VERSION ""

NS_ :

BS_:

BU_: ECU Debugger ACU TCM Dash_Panel Steering_Wheel DTI_Inverter GR_Inverter_1 GR_Inverter_2 GR_Inverter_3 GR_Inverter_4 Charging_SDC Fan_Controller_1 Fan_Controller_2 Fan_Controller_3 Fan_Controller_4 Fan_Controller_5 Fan_Controller_6 Fan_Controller_7 Fan_Controller_8 SAM1 SAM2 SAM3 SAM4 SAM5 SAM6 SAM7 SAM8 SAM9 SAM10 SAM11 SAM12 SAM13 SAM14 SAM15 SAM16 SAM17 SAM18 SAM19 SAM20 LV_DC_DC

BO_ 2147483648 Ping: 8 ECU

 SG_ Millis : 7|32@0- (1,0) [-214748.3648|214748.3647] "ms" Vector__XXX

BO_ 1 Ping: 4 ECU

BO_ 2 ECU_status: 44 ECU

 SG_ GR_Inv_4_RPM : 336|16@1+ (1,0) [0.0|65535.0] "RPM" Vector__XXX

 SG_ GR_Inv_4_Temp : 320|16@1+ (1,0) [0.0|65535.0] "Celsius" Vector__XXX

 SG_ GR_Inv_4_AC_current : 304|16@1+ (1,0) [0.0|65535.0] "Amps" Vector__XXX

 SG_ GR_Inv_3_RPM : 288|16@1+ (1,0) [0.0|65535.0] "RPM" Vector__XXX

 SG_ GR_Inv_3_Temp : 272|16@1+ (1,0) [0.0|65535.0] "Celsius" Vector__XXX

 SG_ GR_Inv_3_AC_current : 256|16@1+ (1,0) [0.0|65535.0] "Amps" Vector__XXX

 SG_ GR_Inv_2_RPM : 240|16@1+ (1,0) [0.0|65535.0] "RPM" Vector__XXX

 SG_ GR_Inv_2_Temp : 224|16@1+ (1,0) [0.0|65535.0] "Celsius" Vector__XXX

 SG_ GR_Inv_2_AC_current : 208|16@1+ (1,0) [0.0|65535.0] "Amps" Vector__XXX

 SG_ Inv_1_RPM : 192|16@1+ (1,0) [0.0|65535.0] "RPM" Vector__XXX

 SG_ GR_Inv_1_Temp : 176|16@1+ (1,0) [0.0|65535.0] "Celsius" Vector__XXX

 SG_ GR_Inv_1_AC_current : 160|16@1+ (1,0) [0.0|65535.0] "Amps" Vector__XXX

 SG_ RL_Wheel_RPM : 144|16@1+ (1,0) [0.0|65535.0] "RPM" Vector__XXX

 SG_ RR_Wheel_RPM : 128|16@1+ (1,0) [0.0|65535.0] "RPM" Vector__XXX

 SG_ FL_Wheel_RPM : 112|16@1+ (1,0) [0.0|65535.0] "RPM" Vector__XXX

 SG_ FR_Wheel_RPM : 96|16@1+ (1,0) [0.0|65535.0] "RPM" Vector__XXX

 SG_ Vehicle_Speed : 80|16@1+ (1,0) [0.0|65535.0] "MPH" Vector__XXX

 SG_ Tractive_System_Voltage : 64|16@1+ (1,0) [0.0|65535.0] "Volts" Vector__XXX

 SG_ GLV_State_of_Charge : 56|8@1+ (1,0) [0.0|255.0] "%" Vector__XXX

 SG_ Accumulator_State_of_Charge : 48|8@1+ (1,0) [0.0|255.0] "%" Vector__XXX

 SG_ Max_Cell_Temp : 40|8@1+ (1,0) [0.0|255.0] "Celsius" Vector__XXX

 SG_ Torque_Map : 36|4@1+ (1,0) [0.0|16.0] "~" Vector__XXX

 SG_ Power_Level : 32|4@1+ (1,0) [0.0|15.0] "~" Vector__XXX

 SG_ Reserved_for_future_use : 19|13@1+ (1,0) [0|0] "~" Vector__XXX

 SG_ Steering : 18|1@1+ (1,0) [0.0|1.0] "Bool" Vector__XXX

 SG_ Dash : 17|1@1+ (1,0) [0.0|1.0] "Bool" Vector__XXX

 SG_ Fan_Controller_4 : 16|1@1+ (1,0) [0.0|1.0] "Bool" Vector__XXX

 SG_ Fan_Controller_3 : 15|1@1+ (1,0) [0.0|1.0] "Bool" Vector__XXX

 SG_ Fan_Controller_2 : 14|1@1+ (1,0) [0.0|1.0] "Bool" Vector__XXX

 SG_ Fan_Controller_1 : 13|1@1+ (1,0) [0.0|1.0] "Bool" Vector__XXX

 SG_ GR_Inv_4_Status : 12|1@1+ (1,0) [0.0|1.0] "Bool" Vector__XXX

 SG_ GR_Inv_3_Status : 11|1@1+ (1,0) [0.0|1.0] "Bool" Vector__XXX

 SG_ GR_Inv_2_Status : 10|1@1+ (1,0) [0.0|1.0] "Bool" Vector__XXX

 SG_ GR_Inv_1_Status : 9|1@1+ (1,0) [0.0|1.0] "Bool" Vector__XXX

 SG_ ACU_Node_Status_ : 8|1@1+ (1,0) [0.0|1.0] "Bool" Vector__XXX

 SG_ ECU_State : 0|8@1+ (1,0) [0|0] "Bool" Vector__XXX

BO_ 3 ECU_config: 0 ECU

 SG_ Reserved : 0|1@1+ (1,0) [0|0] "~" Vector__XXX

BO_ 4 ACU_Status: 24 ACU

 SG_ HV_Output_Current : 176|16@1+ (1,0) [0.0|65535.0] "Amps" Vector__XXX

 SG_ HV_Input_Current : 160|16@1+ (1,0) [0.0|65535.0] "Amps" Vector__XXX

 SG_ HV_Output_Voltage : 144|16@1+ (1,0) [0.0|65535.0] "Volts" Vector__XXX

 SG_ HV_Input_Voltage : 128|16@1+ (1,0) [0.0|65535.0] "Volts" Vector__XXX

 SG_ Software_Latch : 122|6@1+ (1,0) [0.0|1.0] "Bool" Vector__XXX

 SG_ IR__State : 121|1@1+ (1,0) [0.0|1.0] "Bool" Vector__XXX

 SG_ IR____Precharge_State : 120|1@1+ (1,0) [0.0|1.0] "Bool" Vector__XXX

 SG_ Precharge_Error : 112|8@1+ (1,0) [0.0|1.0] "Bool" Vector__XXX

 SG_ Under_Voltage_SDC_Warning : 111|1@1+ (1,0) [0.0|1.0] "Bool" Vector__XXX

 SG_ Under_Voltage_12v_Warning : 110|1@1+ (1,0) [0.0|1.0] "Bool" Vector__XXX

 SG_ Under_Voltage_20v_Warning : 109|1@1+ (1,0) [0.0|1.0] "Bool" Vector__XXX

 SG_ Under_Current_Error : 108|1@1+ (1,0) [0.0|1.0] "Bool" Vector__XXX

 SG_ Over_Current_Error : 107|1@1+ (1,0) [0.0|1.0] "Bool" Vector__XXX

 SG_ Under_Voltage_Error : 106|1@1+ (1,0) [0.0|1.0] "Bool" Vector__XXX

 SG_ Over_Voltage_Error : 105|1@1+ (1,0) [0.0|1.0] "Bool" Vector__XXX

 SG_ Over_Temp_Error : 104|1@1+ (1,0) [0.0|1.0] "Bool" Vector__XXX

 SG_ Max_Cell_Temp : 96|8@1+ (1,0) [0.0|255.0] "Celsius" Vector__XXX

 SG_ Min_Cell_Voltage : 88|8@1+ (1,0) [0.0|255.0] "Volts" Vector__XXX

 SG_ SDC_Voltage : 80|8@1+ (1,0) [0.0|255.0] "Volts" Vector__XXX

 SG_ v12v_Voltage : 72|8@1+ (1,0) [0.0|255.0] "Volts" Vector__XXX

 SG_ v20v_Voltage : 64|8@1+ (1,0) [0.0|255.0] "Volts" Vector__XXX

 SG_ GLV_SOC : 56|8@1+ (1,0) [0.0|255.0] "%" Vector__XXX

 SG_ Accumulator_SOC : 48|8@1+ (1,0) [0.0|255.0] "%" Vector__XXX

 SG_ Accumulator_Current : 32|16@1+ (1,0) [0.0|65535.0] "Amps" Vector__XXX

 SG_ TS_Voltage : 16|16@1+ (1,0) [0.0|65535.0] "Volts" Vector__XXX

 SG_ Accumulator_Voltage : 0|16@1+ (1,0) [0.0|65535.0] "Volts" Vector__XXX

BO_ 5 ACU_Precharge: 1 ACU

 SG_ Set_TS_Active : 0|8@1+ (1,0) [0.0|1.0] "Bool" Vector__XXX

BO_ 6 ACU_Config_Charge_Parameters: 4 ACU

 SG_ Charge_Current : 16|16@1+ (1,0) [0.0|65535.0] "Amps" Vector__XXX

 SG_ Charge_Voltage : 0|16@1+ (1,0) [0.0|65535.0] "Volts" Vector__XXX

BO_ 7 ACU_Config_Operational_Parameter: 2 ACU

 SG_ Max_Cell_Temperature : 8|8@1+ (1,0) [0.0|255.0] "Celsius" Vector__XXX

 SG_ Minimium_Cell_Voltage : 0|8@1+ (1,0) [0.0|255.0] "Volts" Vector__XXX

BO_ 8 ACU_Cell_Data_1: 64 ACU

 SG_ Cell_31_Temp : 504|8@1+ (1,0) [0.0|255.0] "Celsius" Vector__XXX

 SG_ Cell_31_Voltage : 496|8@1+ (1,0) [0.0|255.0] "Volts" Vector__XXX

 SG_ Cell_30_Temp : 488|8@1+ (1,0) [0.0|255.0] "Celsius" Vector__XXX

 SG_ Cell_30_Voltage : 480|8@1+ (1,0) [0.0|255.0] "Volts" Vector__XXX

 SG_ Cell_29_Temp : 472|8@1+ (1,0) [0.0|255.0] "Celsius" Vector__XXX

 SG_ Cell_29_Voltage : 464|8@1+ (1,0) [0.0|255.0] "Volts" Vector__XXX

 SG_ Cell_28_Temp : 456|8@1+ (1,0) [0.0|255.0] "Celsius" Vector__XXX

 SG_ Cell_28_Voltage : 448|8@1+ (1,0) [0.0|255.0] "Volts" Vector__XXX

 SG_ Cell_27_Temp : 440|8@1+ (1,0) [0.0|255.0] "Celsius" Vector__XXX

 SG_ Cell_27_Voltage : 432|8@1+ (1,0) [0.0|255.0] "Volts" Vector__XXX

 SG_ Cell_26_Temp : 424|8@1+ (1,0) [0.0|255.0] "Celsius" Vector__XXX

 SG_ Cell_26_Voltage : 416|8@1+ (1,0) [0.0|255.0] "Volts" Vector__XXX

 SG_ Cell_25_Temp : 408|8@1+ (1,0) [0.0|255.0] "Celsius" Vector__XXX

 SG_ Cell_25_Voltage : 400|8@1+ (1,0) [0.0|255.0] "Volts" Vector__XXX

 SG_ Cell_24_Temp : 392|8@1+ (1,0) [0.0|255.0] "Celsius" Vector__XXX

 SG_ Cell_24_Voltage : 384|8@1+ (1,0) [0.0|255.0] "Volts" Vector__XXX

 SG_ Cell_23_Temp : 376|8@1+ (1,0) [0.0|255.0] "Celsius" Vector__XXX

 SG_ Cell_23_Voltage : 368|8@1+ (1,0) [0.0|255.0] "Volts" Vector__XXX

 SG_ Cell_22_Temp : 360|8@1+ (1,0) [0.0|255.0] "Celsius" Vector__XXX

 SG_ Cell_22_Voltage : 352|8@1+ (1,0) [0.0|255.0] "Volts" Vector__XXX

 SG_ Cell_21_Temp : 344|8@1+ (1,0) [0.0|255.0] "Celsius" Vector__XXX

 SG_ Cell_21_Voltage : 336|8@1+ (1,0) [0.0|255.0] "Volts" Vector__XXX

 SG_ Cell_20_Temp : 328|8@1+ (1,0) [0.0|255.0] "Celsius" Vector__XXX

 SG_ Cell_20_Voltage : 320|8@1+ (1,0) [0.0|255.0] "Volts" Vector__XXX

 SG_ Cell_19_Temp : 312|8@1+ (1,0) [0.0|255.0] "Celsius" Vector__XXX

 SG_ Cell_19_Voltage : 304|8@1+ (1,0) [0.0|255.0] "Volts" Vector__XXX

 SG_ Cell_18_Temp : 296|8@1+ (1,0) [0.0|255.0] "Celsius" Vector__XXX

 SG_ Cell_18_Voltage : 288|8@1+ (1,0) [0.0|255.0] "Volts" Vector__XXX

 SG_ Cell_17_Temp : 280|8@1+ (1,0) [0.0|255.0] "Celsius" Vector__XXX

 SG_ Cell_17_Voltage : 272|8@1+ (1,0) [0.0|255.0] "Volts" Vector__XXX

 SG_ Cell_16_Temp : 264|8@1+ (1,0) [0.0|255.0] "Celsius" Vector__XXX

 SG_ Cell_16_Voltage : 256|8@1+ (1,0) [0.0|255.0] "Volts" Vector__XXX

 SG_ Cell_15_Temp : 248|8@1+ (1,0) [0.0|255.0] "Celsius" Vector__XXX

 SG_ Cell_15_Voltage : 240|8@1+ (1,0) [0.0|255.0] "Volts" Vector__XXX

 SG_ Cell_14_Temp : 232|8@1+ (1,0) [0.0|255.0] "Celsius" Vector__XXX

 SG_ Cell_14_Voltage : 224|8@1+ (1,0) [0.0|255.0] "Volts" Vector__XXX

 SG_ Cell_13_Temp : 216|8@1+ (1,0) [0.0|255.0] "Celsius" Vector__XXX

 SG_ Cell_13_Voltage : 208|8@1+ (1,0) [0.0|255.0] "Volts" Vector__XXX

 SG_ Cell_12_Temp : 200|8@1+ (1,0) [0.0|255.0] "Celsius" Vector__XXX

 SG_ Cell_12_Voltage : 192|8@1+ (1,0) [0.0|255.0] "Volts" Vector__XXX

 SG_ Cell_11_Temp : 184|8@1+ (1,0) [0.0|255.0] "Celsius" Vector__XXX

 SG_ Cell_11_Voltage : 176|8@1+ (1,0) [0.0|255.0] "Volts" Vector__XXX

 SG_ Cell_10_Temp : 168|8@1+ (1,0) [0.0|255.0] "Celsius" Vector__XXX

 SG_ Cell_10_Voltage : 160|8@1+ (1,0) [0.0|255.0] "Volts" Vector__XXX

 SG_ Cell_9_Temp : 152|8@1+ (1,0) [0.0|255.0] "Celsius" Vector__XXX

 SG_ Cell_9_Voltage : 144|8@1+ (1,0) [0.0|255.0] "Volts" Vector__XXX

 SG_ Cell_8_Temp : 136|8@1+ (1,0) [0.0|255.0] "Celsius" Vector__XXX

 SG_ Cell_8_Voltage : 128|8@1+ (1,0) [0.0|255.0] "Volts" Vector__XXX

 SG_ Cell_7_Temp : 120|8@1+ (1,0) [0.0|255.0] "Celsius" Vector__XXX

 SG_ Cell_7_Voltage : 112|8@1+ (1,0) [0.0|255.0] "Volts" Vector__XXX

 SG_ Cell_6_Temp : 104|8@1+ (1,0) [0.0|255.0] "Celsius" Vector__XXX

 SG_ Cell_6_Voltage : 96|8@1+ (1,0) [0.0|255.0] "Volts" Vector__XXX

 SG_ Cell_5_Temp : 88|8@1+ (1,0) [0.0|255.0] "Celsius" Vector__XXX

 SG_ Cell_5_Voltage : 80|8@1+ (1,0) [0.0|255.0] "Volts" Vector__XXX

 SG_ Cell_4_Temp : 72|8@1+ (1,0) [0.0|255.0] "Celsius" Vector__XXX

 SG_ Cell_4_Voltage : 64|8@1+ (1,0) [0.0|255.0] "Volts" Vector__XXX

 SG_ Cell_3_Temp : 56|8@1+ (1,0) [0.0|255.0] "Celsius" Vector__XXX

 SG_ Cell_3_Voltage : 48|8@1+ (1,0) [0.0|255.0] "Volts" Vector__XXX

 SG_ Cell_2_Temp : 40|8@1+ (1,0) [0.0|255.0] "Celsius" Vector__XXX

 SG_ Cell_2_Voltage : 32|8@1+ (1,0) [0.0|255.0] "Volts" Vector__XXX

 SG_ Cell_1_Temp : 24|8@1+ (1,0) [0.0|255.0] "Celsius" Vector__XXX

 SG_ Cell_1_Voltage : 16|8@1+ (1,0) [0.0|255.0] "Volts" Vector__XXX

 SG_ Cell_0_Temp : 8|8@1+ (1,0) [0.0|255.0] "Celsius" Vector__XXX

 SG_ Cell_0_Voltage : 0|8@1+ (1,0) [0.0|255.0] "Volts" Vector__XXX

BO_ 9 ACU_Cell_Data_2: 64 ACU

 SG_ Cell_63_Temp : 504|8@1+ (1,0) [0.0|255.0] "Celsius" Vector__XXX

 SG_ Cell_63_Voltage : 496|8@1+ (1,0) [0.0|255.0] "Volts" Vector__XXX

 SG_ Cell_62_Temp : 488|8@1+ (1,0) [0.0|255.0] "Celsius" Vector__XXX

 SG_ Cell_62_Voltage : 480|8@1+ (1,0) [0.0|255.0] "Volts" Vector__XXX

 SG_ Cell_61_Temp : 472|8@1+ (1,0) [0.0|255.0] "Celsius" Vector__XXX

 SG_ Cell_61_Voltage : 464|8@1+ (1,0) [0.0|255.0] "Volts" Vector__XXX

 SG_ Cell_60_Temp : 456|8@1+ (1,0) [0.0|255.0] "Celsius" Vector__XXX

 SG_ Cell_60_Voltage : 448|8@1+ (1,0) [0.0|255.0] "Volts" Vector__XXX

 SG_ Cell_59_Temp : 440|8@1+ (1,0) [0.0|255.0] "Celsius" Vector__XXX

 SG_ Cell_59_Voltage : 432|8@1+ (1,0) [0.0|255.0] "Volts" Vector__XXX

 SG_ Cell_58_Temp : 424|8@1+ (1,0) [0.0|255.0] "Celsius" Vector__XXX

 SG_ Cell_58_Voltage : 416|8@1+ (1,0) [0.0|255.0] "Volts" Vector__XXX

 SG_ Cell_57_Temp : 408|8@1+ (1,0) [0.0|255.0] "Celsius" Vector__XXX

 SG_ Cell_57_Voltage : 400|8@1+ (1,0) [0.0|255.0] "Volts" Vector__XXX

 SG_ Cell_56_Temp : 392|8@1+ (1,0) [0.0|255.0] "Celsius" Vector__XXX

 SG_ Cell_56_Voltage : 384|8@1+ (1,0) [0.0|255.0] "Volts" Vector__XXX

 SG_ Cell_55_Temp : 376|8@1+ (1,0) [0.0|255.0] "Celsius" Vector__XXX

 SG_ Cell_55_Voltage : 368|8@1+ (1,0) [0.0|255.0] "Volts" Vector__XXX

 SG_ Cell_54_Temp : 360|8@1+ (1,0) [0.0|255.0] "Celsius" Vector__XXX

 SG_ Cell_54_Voltage : 352|8@1+ (1,0) [0.0|255.0] "Volts" Vector__XXX

 SG_ Cell_53_Temp : 344|8@1+ (1,0) [0.0|255.0] "Celsius" Vector__XXX

 SG_ Cell_53_Voltage : 336|8@1+ (1,0) [0.0|255.0] "Volts" Vector__XXX

 SG_ Cell_52_Temp : 328|8@1+ (1,0) [0.0|255.0] "Celsius" Vector__XXX

 SG_ Cell_52_Voltage : 320|8@1+ (1,0) [0.0|255.0] "Volts" Vector__XXX

 SG_ Cell_51_Temp : 312|8@1+ (1,0) [0.0|255.0] "Celsius" Vector__XXX

 SG_ Cell_51_Voltage : 304|8@1+ (1,0) [0.0|255.0] "Volts" Vector__XXX

 SG_ Cell_50_Temp : 296|8@1+ (1,0) [0.0|255.0] "Celsius" Vector__XXX

 SG_ Cell_50_Voltage : 288|8@1+ (1,0) [0.0|255.0] "Volts" Vector__XXX

 SG_ Cell_49_Temp : 280|8@1+ (1,0) [0.0|255.0] "Celsius" Vector__XXX

 SG_ Cell_49_Voltage : 272|8@1+ (1,0) [0.0|255.0] "Volts" Vector__XXX

 SG_ Cell_48_Temp : 264|8@1+ (1,0) [0.0|255.0] "Celsius" Vector__XXX

 SG_ Cell_48_Voltage : 256|8@1+ (1,0) [0.0|255.0] "Volts" Vector__XXX

 SG_ Cell_47_Temp : 248|8@1+ (1,0) [0.0|255.0] "Celsius" Vector__XXX

 SG_ Cell_47_Voltage : 240|8@1+ (1,0) [0.0|255.0] "Volts" Vector__XXX

 SG_ Cell_46_Temp : 232|8@1+ (1,0) [0.0|255.0] "Celsius" Vector__XXX

 SG_ Cell_46_Voltage : 224|8@1+ (1,0) [0.0|255.0] "Volts" Vector__XXX

 SG_ Cell_45_Temp : 216|8@1+ (1,0) [0.0|255.0] "Celsius" Vector__XXX

 SG_ Cell_45_Voltage : 208|8@1+ (1,0) [0.0|255.0] "Volts" Vector__XXX

 SG_ Cell_44_Temp : 200|8@1+ (1,0) [0.0|255.0] "Celsius" Vector__XXX

 SG_ Cell_44_Voltage : 192|8@1+ (1,0) [0.0|255.0] "Volts" Vector__XXX

 SG_ Cell_43_Temp : 184|8@1+ (1,0) [0.0|255.0] "Celsius" Vector__XXX

 SG_ Cell_43_Voltage : 176|8@1+ (1,0) [0.0|255.0] "Volts" Vector__XXX

 SG_ Cell_42_Temp : 168|8@1+ (1,0) [0.0|255.0] "Celsius" Vector__XXX

 SG_ Cell_42_Voltage : 160|8@1+ (1,0) [0.0|255.0] "Volts" Vector__XXX

 SG_ Cell_41_Temp : 152|8@1+ (1,0) [0.0|255.0] "Celsius" Vector__XXX

 SG_ Cell_41_Voltage : 144|8@1+ (1,0) [0.0|255.0] "Volts" Vector__XXX

 SG_ Cell_40_Temp : 136|8@1+ (1,0) [0.0|255.0] "Celsius" Vector__XXX

 SG_ Cell_40_Voltage : 128|8@1+ (1,0) [0.0|255.0] "Volts" Vector__XXX

 SG_ Cell_39_Temp : 120|8@1+ (1,0) [0.0|255.0] "Celsius" Vector__XXX

 SG_ Cell_39_Voltage : 112|8@1+ (1,0) [0.0|255.0] "Volts" Vector__XXX

 SG_ Cell_38_Temp : 104|8@1+ (1,0) [0.0|255.0] "Celsius" Vector__XXX

 SG_ Cell_38_Voltage : 96|8@1+ (1,0) [0.0|255.0] "Volts" Vector__XXX

 SG_ Cell_37_Temp : 88|8@1+ (1,0) [0.0|255.0] "Celsius" Vector__XXX

 SG_ Cell_37_Voltage : 80|8@1+ (1,0) [0.0|255.0] "Volts" Vector__XXX

 SG_ Cell_36_Temp : 72|8@1+ (1,0) [0.0|255.0] "Celsius" Vector__XXX

 SG_ Cell_36_Voltage : 64|8@1+ (1,0) [0.0|255.0] "Volts" Vector__XXX

 SG_ Cell_35_Temp : 56|8@1+ (1,0) [0.0|255.0] "Celsius" Vector__XXX

 SG_ Cell_35_Voltage : 48|8@1+ (1,0) [0.0|255.0] "Volts" Vector__XXX

 SG_ Cell_34_Temp : 40|8@1+ (1,0) [0.0|255.0] "Celsius" Vector__XXX

 SG_ Cell_34_Voltage : 32|8@1+ (1,0) [0.0|255.0] "Volts" Vector__XXX

 SG_ Cell_33_Temp : 24|8@1+ (1,0) [0.0|255.0] "Celsius" Vector__XXX

 SG_ Cell_33_Voltage : 16|8@1+ (1,0) [0.0|255.0] "Volts" Vector__XXX

 SG_ Cell_32_Temp : 8|8@1+ (1,0) [0.0|255.0] "Celsius" Vector__XXX

 SG_ Cell_32_Voltage : 0|8@1+ (1,0) [0.0|255.0] "Volts" Vector__XXX

BO_ 10 ACU_Cell_Data_3: 64 ACU

 SG_ Cell_95_Temp : 504|8@1+ (1,0) [0.0|255.0] "Celsius" Vector__XXX

 SG_ Cell_95_Voltage : 496|8@1+ (1,0) [0.0|255.0] "Volts" Vector__XXX

 SG_ Cell_94_Temp : 488|8@1+ (1,0) [0.0|255.0] "Celsius" Vector__XXX

 SG_ Cell_94_Voltage : 480|8@1+ (1,0) [0.0|255.0] "Volts" Vector__XXX

 SG_ Cell_93_Temp : 472|8@1+ (1,0) [0.0|255.0] "Celsius" Vector__XXX

 SG_ Cell_93_Voltage : 464|8@1+ (1,0) [0.0|255.0] "Volts" Vector__XXX

 SG_ Cell_92_Temp : 456|8@1+ (1,0) [0.0|255.0] "Celsius" Vector__XXX

 SG_ Cell_92_Voltage : 448|8@1+ (1,0) [0.0|255.0] "Volts" Vector__XXX

 SG_ Cell_91_Temp : 440|8@1+ (1,0) [0.0|255.0] "Celsius" Vector__XXX

 SG_ Cell_91_Voltage : 432|8@1+ (1,0) [0.0|255.0] "Volts" Vector__XXX

 SG_ Cell_90_Temp : 424|8@1+ (1,0) [0.0|255.0] "Celsius" Vector__XXX

 SG_ Cell_90_Voltage : 416|8@1+ (1,0) [0.0|255.0] "Volts" Vector__XXX

 SG_ Cell_89_Temp : 408|8@1+ (1,0) [0.0|255.0] "Celsius" Vector__XXX

 SG_ Cell_89_Voltage : 400|8@1+ (1,0) [0.0|255.0] "Volts" Vector__XXX

 SG_ Cell_88_Temp : 392|8@1+ (1,0) [0.0|255.0] "Celsius" Vector__XXX

 SG_ Cell_88_Voltage : 384|8@1+ (1,0) [0.0|255.0] "Volts" Vector__XXX

 SG_ Cell_87_Temp : 376|8@1+ (1,0) [0.0|255.0] "Celsius" Vector__XXX

 SG_ Cell_87_Voltage : 368|8@1+ (1,0) [0.0|255.0] "Volts" Vector__XXX

 SG_ Cell_86_Temp : 360|8@1+ (1,0) [0.0|255.0] "Celsius" Vector__XXX

 SG_ Cell_86_Voltage : 352|8@1+ (1,0) [0.0|255.0] "Volts" Vector__XXX

 SG_ Cell_85_Temp : 344|8@1+ (1,0) [0.0|255.0] "Celsius" Vector__XXX

 SG_ Cell_85_Voltage : 336|8@1+ (1,0) [0.0|255.0] "Volts" Vector__XXX

 SG_ Cell_84_Temp : 328|8@1+ (1,0) [0.0|255.0] "Celsius" Vector__XXX

 SG_ Cell_84_Voltage : 320|8@1+ (1,0) [0.0|255.0] "Volts" Vector__XXX

 SG_ Cell_83_Temp : 312|8@1+ (1,0) [0.0|255.0] "Celsius" Vector__XXX

 SG_ Cell_83_Voltage : 304|8@1+ (1,0) [0.0|255.0] "Volts" Vector__XXX

 SG_ Cell_82_Temp : 296|8@1+ (1,0) [0.0|255.0] "Celsius" Vector__XXX

 SG_ Cell_82_Voltage : 288|8@1+ (1,0) [0.0|255.0] "Volts" Vector__XXX

 SG_ Cell_81_Temp : 280|8@1+ (1,0) [0.0|255.0] "Celsius" Vector__XXX

 SG_ Cell_81_Voltage : 272|8@1+ (1,0) [0.0|255.0] "Volts" Vector__XXX

 SG_ Cell_80_Temp : 264|8@1+ (1,0) [0.0|255.0] "Celsius" Vector__XXX

 SG_ Cell_80_Voltage : 256|8@1+ (1,0) [0.0|255.0] "Volts" Vector__XXX

 SG_ Cell_79_Temp : 248|8@1+ (1,0) [0.0|255.0] "Celsius" Vector__XXX

 SG_ Cell_79_Voltage : 240|8@1+ (1,0) [0.0|255.0] "Volts" Vector__XXX

 SG_ Cell_78_Temp : 232|8@1+ (1,0) [0.0|255.0] "Celsius" Vector__XXX

 SG_ Cell_78_Voltage : 224|8@1+ (1,0) [0.0|255.0] "Volts" Vector__XXX

 SG_ Cell_77_Temp : 216|8@1+ (1,0) [0.0|255.0] "Celsius" Vector__XXX

 SG_ Cell_77_Voltage : 208|8@1+ (1,0) [0.0|255.0] "Volts" Vector__XXX

 SG_ Cell_76_Temp : 200|8@1+ (1,0) [0.0|255.0] "Celsius" Vector__XXX

 SG_ Cell_76_Voltage : 192|8@1+ (1,0) [0.0|255.0] "Volts" Vector__XXX

 SG_ Cell_75_Temp : 184|8@1+ (1,0) [0.0|255.0] "Celsius" Vector__XXX

 SG_ Cell_75_Voltage : 176|8@1+ (1,0) [0.0|255.0] "Volts" Vector__XXX

 SG_ Cell_74_Temp : 168|8@1+ (1,0) [0.0|255.0] "Celsius" Vector__XXX

 SG_ Cell_74_Voltage : 160|8@1+ (1,0) [0.0|255.0] "Volts" Vector__XXX

 SG_ Cell_73_Temp : 152|8@1+ (1,0) [0.0|255.0] "Celsius" Vector__XXX

 SG_ Cell_73_Voltage : 144|8@1+ (1,0) [0.0|255.0] "Volts" Vector__XXX

 SG_ Cell_72_Temp : 136|8@1+ (1,0) [0.0|255.0] "Celsius" Vector__XXX

 SG_ Cell_72_Voltage : 128|8@1+ (1,0) [0.0|255.0] "Volts" Vector__XXX

 SG_ Cell_71_Temp : 120|8@1+ (1,0) [0.0|255.0] "Celsius" Vector__XXX

 SG_ Cell_71_Voltage : 112|8@1+ (1,0) [0.0|255.0] "Volts" Vector__XXX

 SG_ Cell_70_Temp : 104|8@1+ (1,0) [0.0|255.0] "Celsius" Vector__XXX

 SG_ Cell_70_Voltage : 96|8@1+ (1,0) [0.0|255.0] "Volts" Vector__XXX

 SG_ Cell_69_Temp : 88|8@1+ (1,0) [0.0|255.0] "Celsius" Vector__XXX

 SG_ Cell_69_Voltage : 80|8@1+ (1,0) [0.0|255.0] "Volts" Vector__XXX

 SG_ Cell_68_Temp : 72|8@1+ (1,0) [0.0|255.0] "Celsius" Vector__XXX

 SG_ Cell_68_Voltage : 64|8@1+ (1,0) [0.0|255.0] "Volts" Vector__XXX

 SG_ Cell_67_Temp : 56|8@1+ (1,0) [0.0|255.0] "Celsius" Vector__XXX

 SG_ Cell_67_Voltage : 48|8@1+ (1,0) [0.0|255.0] "Volts" Vector__XXX

 SG_ Cell_66_Temp : 40|8@1+ (1,0) [0.0|255.0] "Celsius" Vector__XXX

 SG_ Cell_66_Voltage : 32|8@1+ (1,0) [0.0|255.0] "Volts" Vector__XXX

 SG_ Cell_65_Temp : 24|8@1+ (1,0) [0.0|255.0] "Celsius" Vector__XXX

 SG_ Cell_65_Voltage : 16|8@1+ (1,0) [0.0|255.0] "Volts" Vector__XXX

 SG_ Cell_64_Temp : 8|8@1+ (1,0) [0.0|255.0] "Celsius" Vector__XXX

 SG_ Cell_64_Voltage : 0|8@1+ (1,0) [0.0|255.0] "Volts" Vector__XXX

BO_ 11 ACU_Cell_Data_4: 64 ACU

 SG_ Cell_127_Temp : 504|8@1+ (1,0) [0.0|255.0] "Celsius" Vector__XXX

 SG_ Cell_127_Voltage : 496|8@1+ (1,0) [0.0|255.0] "Volts" Vector__XXX

 SG_ Cell_126_Temp : 488|8@1+ (1,0) [0.0|255.0] "Celsius" Vector__XXX

 SG_ Cell_126_Voltage : 480|8@1+ (1,0) [0.0|255.0] "Volts" Vector__XXX

 SG_ Cell_125_Temp : 472|8@1+ (1,0) [0.0|255.0] "Celsius" Vector__XXX

 SG_ Cell_125_Voltage : 464|8@1+ (1,0) [0.0|255.0] "Volts" Vector__XXX

 SG_ Cell_124_Temp : 456|8@1+ (1,0) [0.0|255.0] "Celsius" Vector__XXX

 SG_ Cell_124_Voltage : 448|8@1+ (1,0) [0.0|255.0] "Volts" Vector__XXX

 SG_ Cell_123_Temp : 440|8@1+ (1,0) [0.0|255.0] "Celsius" Vector__XXX

 SG_ Cell_123_Voltage : 432|8@1+ (1,0) [0.0|255.0] "Volts" Vector__XXX

 SG_ Cell_122_Temp : 424|8@1+ (1,0) [0.0|255.0] "Celsius" Vector__XXX

 SG_ Cell_122_Voltage : 416|8@1+ (1,0) [0.0|255.0] "Volts" Vector__XXX

 SG_ Cell_121_Temp : 408|8@1+ (1,0) [0.0|255.0] "Celsius" Vector__XXX

 SG_ Cell_121_Voltage : 400|8@1+ (1,0) [0.0|255.0] "Volts" Vector__XXX

 SG_ Cell_120_Temp : 392|8@1+ (1,0) [0.0|255.0] "Celsius" Vector__XXX

 SG_ Cell_120_Voltage : 384|8@1+ (1,0) [0.0|255.0] "Volts" Vector__XXX

 SG_ Cell_119_Temp : 376|8@1+ (1,0) [0.0|255.0] "Celsius" Vector__XXX

 SG_ Cell_119_Voltage : 368|8@1+ (1,0) [0.0|255.0] "Volts" Vector__XXX

 SG_ Cell_118_Temp : 360|8@1+ (1,0) [0.0|255.0] "Celsius" Vector__XXX

 SG_ Cell_118_Voltage : 352|8@1+ (1,0) [0.0|255.0] "Volts" Vector__XXX

 SG_ Cell_117_Temp : 344|8@1+ (1,0) [0.0|255.0] "Celsius" Vector__XXX

 SG_ Cell_117_Voltage : 336|8@1+ (1,0) [0.0|255.0] "Volts" Vector__XXX

 SG_ Cell_116_Temp : 328|8@1+ (1,0) [0.0|255.0] "Celsius" Vector__XXX

 SG_ Cell_116_Voltage : 320|8@1+ (1,0) [0.0|255.0] "Volts" Vector__XXX

 SG_ Cell_115_Temp : 312|8@1+ (1,0) [0.0|255.0] "Celsius" Vector__XXX

 SG_ Cell_115_Voltage : 304|8@1+ (1,0) [0.0|255.0] "Volts" Vector__XXX

 SG_ Cell_114_Temp : 296|8@1+ (1,0) [0.0|255.0] "Celsius" Vector__XXX

 SG_ Cell_114_Voltage : 288|8@1+ (1,0) [0.0|255.0] "Volts" Vector__XXX

 SG_ Cell_113_Temp : 280|8@1+ (1,0) [0.0|255.0] "Celsius" Vector__XXX

 SG_ Cell_113_Voltage : 272|8@1+ (1,0) [0.0|255.0] "Volts" Vector__XXX

 SG_ Cell_112_Temp : 264|8@1+ (1,0) [0.0|255.0] "Celsius" Vector__XXX

 SG_ Cell_112_Voltage : 256|8@1+ (1,0) [0.0|255.0] "Volts" Vector__XXX

 SG_ Cell_111_Temp : 248|8@1+ (1,0) [0.0|255.0] "Celsius" Vector__XXX

 SG_ Cell_111_Voltage : 240|8@1+ (1,0) [0.0|255.0] "Volts" Vector__XXX

 SG_ Cell_110_Temp : 232|8@1+ (1,0) [0.0|255.0] "Celsius" Vector__XXX

 SG_ Cell_110_Voltage : 224|8@1+ (1,0) [0.0|255.0] "Volts" Vector__XXX

 SG_ Cell_109_Temp : 216|8@1+ (1,0) [0.0|255.0] "Celsius" Vector__XXX

 SG_ Cell_109_Voltage : 208|8@1+ (1,0) [0.0|255.0] "Volts" Vector__XXX

 SG_ Cell_108_Temp : 200|8@1+ (1,0) [0.0|255.0] "Celsius" Vector__XXX

 SG_ Cell_108_Voltage : 192|8@1+ (1,0) [0.0|255.0] "Volts" Vector__XXX

 SG_ Cell_107_Temp : 184|8@1+ (1,0) [0.0|255.0] "Celsius" Vector__XXX

 SG_ Cell_107_Voltage : 176|8@1+ (1,0) [0.0|255.0] "Volts" Vector__XXX

 SG_ Cell_106_Temp : 168|8@1+ (1,0) [0.0|255.0] "Celsius" Vector__XXX

 SG_ Cell_106_Voltage : 160|8@1+ (1,0) [0.0|255.0] "Volts" Vector__XXX

 SG_ Cell_105_Temp : 152|8@1+ (1,0) [0.0|255.0] "Celsius" Vector__XXX

 SG_ Cell_105_Voltage : 144|8@1+ (1,0) [0.0|255.0] "Volts" Vector__XXX

 SG_ Cell_104_Temp : 136|8@1+ (1,0) [0.0|255.0] "Celsius" Vector__XXX

 SG_ Cell_104_Voltage : 128|8@1+ (1,0) [0.0|255.0] "Volts" Vector__XXX

 SG_ Cell_103_Temp : 120|8@1+ (1,0) [0.0|255.0] "Celsius" Vector__XXX

 SG_ Cell_103_Voltage : 112|8@1+ (1,0) [0.0|255.0] "Volts" Vector__XXX

 SG_ Cell_102_Temp : 104|8@1+ (1,0) [0.0|255.0] "Celsius" Vector__XXX

 SG_ Cell_102_Voltage : 96|8@1+ (1,0) [0.0|255.0] "Volts" Vector__XXX

 SG_ Cell_101_Temp : 88|8@1+ (1,0) [0.0|255.0] "Celsius" Vector__XXX

 SG_ Cell_101_Voltage : 80|8@1+ (1,0) [0.0|255.0] "Volts" Vector__XXX

 SG_ Cell_100_Temp : 72|8@1+ (1,0) [0.0|255.0] "Celsius" Vector__XXX

 SG_ Cell_100_Voltage : 64|8@1+ (1,0) [0.0|255.0] "Volts" Vector__XXX

 SG_ Cell_99_Temp : 56|8@1+ (1,0) [0.0|255.0] "Celsius" Vector__XXX

 SG_ Cell_99_Voltage : 48|8@1+ (1,0) [0.0|255.0] "Volts" Vector__XXX

 SG_ Cell_98_Temp : 40|8@1+ (1,0) [0.0|255.0] "Celsius" Vector__XXX

 SG_ Cell_98_Voltage : 32|8@1+ (1,0) [0.0|255.0] "Volts" Vector__XXX

 SG_ Cell_97_Temp : 24|8@1+ (1,0) [0.0|255.0] "Celsius" Vector__XXX

 SG_ Cell_97_Voltage : 16|8@1+ (1,0) [0.0|255.0] "Volts" Vector__XXX

 SG_ Cell_96_Temp : 8|8@1+ (1,0) [0.0|255.0] "Celsius" Vector__XXX

 SG_ Cell_96_Voltage : 0|8@1+ (1,0) [0.0|255.0] "Volts" Vector__XXX

BO_ 12 ACU_Cell_Data_5: 64 ACU

 SG_ Cell_159_Temp : 504|8@1+ (1,0) [0.0|255.0] "Celsius" Vector__XXX

 SG_ Cell_159_Voltage : 496|8@1+ (1,0) [0.0|255.0] "Volts" Vector__XXX

 SG_ Cell_158_Temp : 488|8@1+ (1,0) [0.0|255.0] "Celsius" Vector__XXX

 SG_ Cell_158_Voltage : 480|8@1+ (1,0) [0.0|255.0] "Volts" Vector__XXX

 SG_ Cell_157_Temp : 472|8@1+ (1,0) [0.0|255.0] "Celsius" Vector__XXX

 SG_ Cell_157_Voltage : 464|8@1+ (1,0) [0.0|255.0] "Volts" Vector__XXX

 SG_ Cell_156_Temp : 456|8@1+ (1,0) [0.0|255.0] "Celsius" Vector__XXX

 SG_ Cell_156_Voltage : 448|8@1+ (1,0) [0.0|255.0] "Volts" Vector__XXX

 SG_ Cell_155_Temp : 440|8@1+ (1,0) [0.0|255.0] "Celsius" Vector__XXX

 SG_ Cell_155_Voltage : 432|8@1+ (1,0) [0.0|255.0] "Volts" Vector__XXX

 SG_ Cell_154_Temp : 424|8@1+ (1,0) [0.0|255.0] "Celsius" Vector__XXX

 SG_ Cell_154_Voltage : 416|8@1+ (1,0) [0.0|255.0] "Volts" Vector__XXX

 SG_ Cell_153_Temp : 408|8@1+ (1,0) [0.0|255.0] "Celsius" Vector__XXX

 SG_ Cell_153_Voltage : 400|8@1+ (1,0) [0.0|255.0] "Volts" Vector__XXX

 SG_ Cell_152_Temp : 392|8@1+ (1,0) [0.0|255.0] "Celsius" Vector__XXX

 SG_ Cell_152_Voltage : 384|8@1+ (1,0) [0.0|255.0] "Volts" Vector__XXX

 SG_ Cell_151_Temp : 376|8@1+ (1,0) [0.0|255.0] "Celsius" Vector__XXX

 SG_ Cell_151_Voltage : 368|8@1+ (1,0) [0.0|255.0] "Volts" Vector__XXX

 SG_ Cell_150_Temp : 360|8@1+ (1,0) [0.0|255.0] "Celsius" Vector__XXX

 SG_ Cell_150_Voltage : 352|8@1+ (1,0) [0.0|255.0] "Volts" Vector__XXX

 SG_ Cell_149_Temp : 344|8@1+ (1,0) [0.0|255.0] "Celsius" Vector__XXX

 SG_ Cell_149_Voltage : 336|8@1+ (1,0) [0.0|255.0] "Volts" Vector__XXX

 SG_ Cell_148_Temp : 328|8@1+ (1,0) [0.0|255.0] "Celsius" Vector__XXX

 SG_ Cell_148_Voltage : 320|8@1+ (1,0) [0.0|255.0] "Volts" Vector__XXX

 SG_ Cell_147_Temp : 312|8@1+ (1,0) [0.0|255.0] "Celsius" Vector__XXX

 SG_ Cell_147_Voltage : 304|8@1+ (1,0) [0.0|255.0] "Volts" Vector__XXX

 SG_ Cell_146_Temp : 296|8@1+ (1,0) [0.0|255.0] "Celsius" Vector__XXX

 SG_ Cell_146_Voltage : 288|8@1+ (1,0) [0.0|255.0] "Volts" Vector__XXX

 SG_ Cell_145_Temp : 280|8@1+ (1,0) [0.0|255.0] "Celsius" Vector__XXX

 SG_ Cell_145_Voltage : 272|8@1+ (1,0) [0.0|255.0] "Volts" Vector__XXX

 SG_ Cell_144_Temp : 264|8@1+ (1,0) [0.0|255.0] "Celsius" Vector__XXX

 SG_ Cell_144_Voltage : 256|8@1+ (1,0) [0.0|255.0] "Volts" Vector__XXX

 SG_ Cell_143_Temp : 248|8@1+ (1,0) [0.0|255.0] "Celsius" Vector__XXX

 SG_ Cell_143_Voltage : 240|8@1+ (1,0) [0.0|255.0] "Volts" Vector__XXX

 SG_ Cell_142_Temp : 232|8@1+ (1,0) [0.0|255.0] "Celsius" Vector__XXX

 SG_ Cell_142_Voltage : 224|8@1+ (1,0) [0.0|255.0] "Volts" Vector__XXX

 SG_ Cell_141_Temp : 216|8@1+ (1,0) [0.0|255.0] "Celsius" Vector__XXX

 SG_ Cell_141_Voltage : 208|8@1+ (1,0) [0.0|255.0] "Volts" Vector__XXX

 SG_ Cell_140_Temp : 200|8@1+ (1,0) [0.0|255.0] "Celsius" Vector__XXX

 SG_ Cell_140_Voltage : 192|8@1+ (1,0) [0.0|255.0] "Volts" Vector__XXX

 SG_ Cell_139_Temp : 184|8@1+ (1,0) [0.0|255.0] "Celsius" Vector__XXX

 SG_ Cell_139_Voltage : 176|8@1+ (1,0) [0.0|255.0] "Volts" Vector__XXX

 SG_ Cell_138_Temp : 168|8@1+ (1,0) [0.0|255.0] "Celsius" Vector__XXX

 SG_ Cell_138_Voltage : 160|8@1+ (1,0) [0.0|255.0] "Volts" Vector__XXX

 SG_ Cell_137_Temp : 152|8@1+ (1,0) [0.0|255.0] "Celsius" Vector__XXX

 SG_ Cell_137_Voltage : 144|8@1+ (1,0) [0.0|255.0] "Volts" Vector__XXX

 SG_ Cell_136_Temp : 136|8@1+ (1,0) [0.0|255.0] "Celsius" Vector__XXX

 SG_ Cell_136_Voltage : 128|8@1+ (1,0) [0.0|255.0] "Volts" Vector__XXX

 SG_ Cell_135_Temp : 120|8@1+ (1,0) [0.0|255.0] "Celsius" Vector__XXX

 SG_ Cell_135_Voltage : 112|8@1+ (1,0) [0.0|255.0] "Volts" Vector__XXX

 SG_ Cell_134_Temp : 104|8@1+ (1,0) [0.0|255.0] "Celsius" Vector__XXX

 SG_ Cell_134_Voltage : 96|8@1+ (1,0) [0.0|255.0] "Volts" Vector__XXX

 SG_ Cell_133_Temp : 88|8@1+ (1,0) [0.0|255.0] "Celsius" Vector__XXX

 SG_ Cell_133_Voltage : 80|8@1+ (1,0) [0.0|255.0] "Volts" Vector__XXX

 SG_ Cell_132_Temp : 72|8@1+ (1,0) [0.0|255.0] "Celsius" Vector__XXX

 SG_ Cell_132_Voltage : 64|8@1+ (1,0) [0.0|255.0] "Volts" Vector__XXX

 SG_ Cell_131_Temp : 56|8@1+ (1,0) [0.0|255.0] "Celsius" Vector__XXX

 SG_ Cell_131_Voltage : 48|8@1+ (1,0) [0.0|255.0] "Volts" Vector__XXX

 SG_ Cell_130_Temp : 40|8@1+ (1,0) [0.0|255.0] "Celsius" Vector__XXX

 SG_ Cell_130_Voltage : 32|8@1+ (1,0) [0.0|255.0] "Volts" Vector__XXX

 SG_ Cell_129_Temp : 24|8@1+ (1,0) [0.0|255.0] "Celsius" Vector__XXX

 SG_ Cell_129_Voltage : 16|8@1+ (1,0) [0.0|255.0] "Volts" Vector__XXX

 SG_ Cell_128_Temp : 8|8@1+ (1,0) [0.0|255.0] "Celsius" Vector__XXX

 SG_ Cell_128_Voltage : 0|8@1+ (1,0) [0.0|255.0] "Volts" Vector__XXX

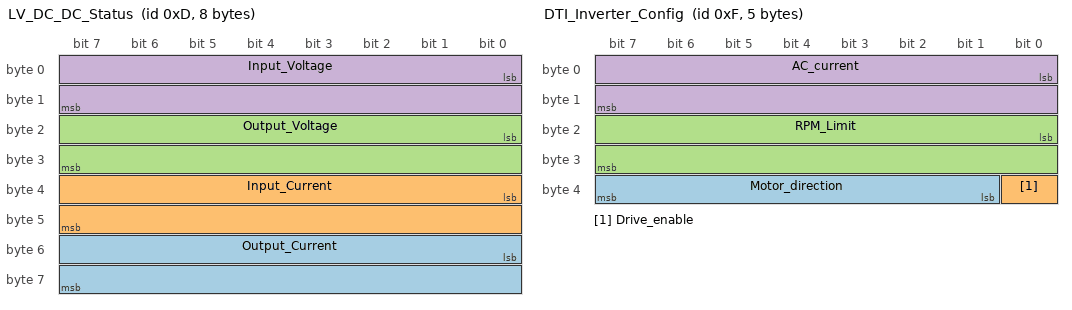
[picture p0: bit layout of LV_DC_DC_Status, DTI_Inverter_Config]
BO_ 13 LV_DC_DC_Status: 8 LV_DC_DC

 SG_ Output_Current : 48|16@1+ (1,0) [0.0|16383.0] "Amps" Vector__XXX

 SG_ Input_Current : 32|16@1+ (1,0) [0.0|16383.0] "Amps" Vector__XXX

 SG_ Output_Voltage : 16|16@1+ (1,0) [0.0|16383.0] "Volts" Vector__XXX

 SG_ Input_Voltage : 0|16@1+ (1,0) [0.0|16383.0] "Volts" Vector__XXX

BO_ 14 DTI_Inverter_Status: 32 DTI_Inverter

 SG_ CAN_Version : 248|8@1+ (1,0) [0|0] "" Vector__XXX

 SG_ Flags : 232|16@1+ (1,0) [0|0] "" Vector__XXX

 SG_ Drive_Enable : 224|8@1+ (1,0) [0|0] "Bool" Vector__XXX

 SG_ Digital_IO__Output_4_ : 223|1@1+ (1,0) [0|0] "Bool" Vector__XXX

 SG_ Digital_IO__Output_3_ : 222|1@1+ (1,0) [0|0] "Bool" Vector__XXX

 SG_ Digital_IO__Output_2_ : 221|1@1+ (1,0) [0|0] "Bool" Vector__XXX

 SG_ Digital_IO__Output_1_ : 220|1@1+ (1,0) [0|0] "Bool" Vector__XXX

 SG_ Digital_IO__Input_4_ : 219|1@1+ (1,0) [0|0] "Bool" Vector__XXX

 SG_ Digital_IO__Input_3_ : 218|1@1+ (1,0) [0|0] "Bool" Vector__XXX

 SG_ Digital_IO__Input_2_ : 217|1@1+ (1,0) [0|0] "Bool" Vector__XXX

 SG_ Digital_IO__Input_1_ : 216|1@1+ (1,0) [0|0] "Bool" Vector__XXX

 SG_ Brake : 208|8@1+ (1,0) [0|0] "%" Vector__XXX

 SG_ Throttle : 200|8@1+ (1,0) [0|0] "%" Vector__XXX

 SG_ FOC_Iq : 168|32@1+ (1,0) [0|0] "Amps" Vector__XXX

 SG_ FOC_Id : 136|32@1+ (1,0) [0|0] "Amps" Vector__XXX

 SG_ Faults : 128|8@1+ (1,0) [0|0] "" Vector__XXX

 SG_ Motor_Temp : 112|16@1+ (1,0) [0|0] "Celsius" Vector__XXX

 SG_ Controller_Temp : 96|16@1+ (1,0) [0|0] "Celsius" Vector__XXX

 SG_ DC_Current : 80|16@1+ (1,0) [0|0] "Amps" Vector__XXX

 SG_ AC_Current : 64|16@1+ (1,0) [0|0] "Amps" Vector__XXX

 SG_ Input_Voltage : 48|16@1+ (1,0) [0|0] "Volts" Vector__XXX

 SG_ Duty_Cycle : 32|16@1+ (1,0) [0|0] "%" Vector__XXX

 SG_ ERPM : 0|32@1+ (1,0) [0|0] "ERPM" Vector__XXX

BO_ 15 DTI_Inverter_Config: 5 DTI_Inverter

 SG_ Motor_direction : 33|7@1+ (1,0) [0.0|1.0] "Enable" Vector__XXX

 SG_ Drive_enable : 32|1@1+ (1,0) [0.0|1.0] "Enable" Vector__XXX

 SG_ RPM_Limit : 16|16@1+ (1,0) [0.0|65535.0] "RPM" Vector__XXX

 SG_ AC_current : 0|16@1+ (1,0) [0.0|65535.0] "Amps" Vector__XXX

BO_ 16 DTI_Inverter_Config_Operational_: 9 DTI_Inverter

 SG_ Max_Brake_DC_Current : 38|34@1+ (1,0) [0|0] "" Vector__XXX

 SG_ Max_DC_Current : 37|1@1+ (1,0) [0|0] "" Vector__XXX

 SG_ Max_Brake_AC_Current : 36|1@1+ (1,0) [0|0] "" Vector__XXX

 SG_ Max_AC_Current : 35|1@1+ (1,0) [0|0] "" Vector__XXX

 SG_ Digital_IO : 34|1@1+ (1,0) [0|0] "" Vector__XXX

BO_ 17 DTI_set_AC_Current: 2 DTI_Inverter

 SG_ AC_Current : 0|16@1+ (1,0) [0|0] "" Vector__XXX

BO_ 18 DTI_set_Target_Brake_Current: 2 DTI_Inverter

 SG_ Target_Brake_Current : 0|16@1+ (1,0) [0|0] "" Vector__XXX

BO_ 19 DTI_set_Target_ERPM: 4 DTI_Inverter

 SG_ Target_ERPM : 0|32@1+ (1,0) [0|0] "" Vector__XXX

BO_ 20 DTI_set_Target_Position: 2 DTI_Inverter

 SG_ Target_Position : 0|16@1+ (1,0) [0|0] "" Vector__XXX

BO_ 21 DTI_set_Relative_AC_Current: 2 DTI_Inverter

 SG_ Relative_AC_Current : 0|16@1+ (1,0) [0|0] "" Vector__XXX

BO_ 22 DTI_set_Relative_AC_Brake_Curren: 2 DTI_Inverter

 SG_ Relative_AC_Brake_Current : 0|16@1+ (1,0) [0|0] "" Vector__XXX

BO_ 23 GR_Inverter_Status: 19 GR_Inverter_1

 SG_ Future_use : 111|41@1+ (1,0) [0.0|1.0] "Bool" Vector__XXX

 SG_ CAN_fault : 110|1@1+ (1,0) [0.0|1.0] "Bool" Vector__XXX

 SG_ Encoder_fault : 109|1@1+ (1,0) [0.0|1.0] "Bool" Vector__XXX

 SG_ Transistor_fault : 108|1@1+ (1,0) [0.0|1.0] "Bool" Vector__XXX

 SG_ Motor_overtemp_fault : 107|1@1+ (1,0) [0.0|1.0] "Bool" Vector__XXX

 SG_ Inv__overtemp_fault : 106|1@1+ (1,0) [0.0|1.0] "Bool" Vector__XXX

 SG_ Under_voltage_fault : 105|1@1+ (1,0) [0.0|1.0] "Bool" Vector__XXX

 SG_ Over_voltage_faults : 104|1@1+ (1,0) [0.0|1.0] "Bool" Vector__XXX

 SG_ Motor_temperature : 96|8@1+ (1,0) [0.0|255.0] "Celsius" Vector__XXX

 SG_ Motor_RPM : 80|16@1+ (1,0) [0.0|65535.0] "RPM" Vector__XXX

 SG_ Water_temperature : 72|8@1+ (1,0) [0.0|255.0] "Celsius" Vector__XXX

 SG_ W_MOSFET_temperature : 64|8@1+ (1,0) [0.0|255.0] "Celsius" Vector__XXX

 SG_ V_MOSFET_temperature : 56|8@1+ (1,0) [0.0|255.0] "Celsius" Vector__XXX

 SG_ U_MOSFET_temperature : 48|8@1+ (1,0) [0.0|255.0] "Celsius" Vector__XXX

 SG_ DC_voltage : 32|16@1+ (1,0) [0.0|65535.0] "Volts" Vector__XXX

 SG_ DC_current : 16|16@1+ (1,0) [0.0|65535.0] "Amps" Vector__XXX

 SG_ AC_current : 0|16@1+ (1,0) [0.0|65535.0] "Amps" Vector__XXX

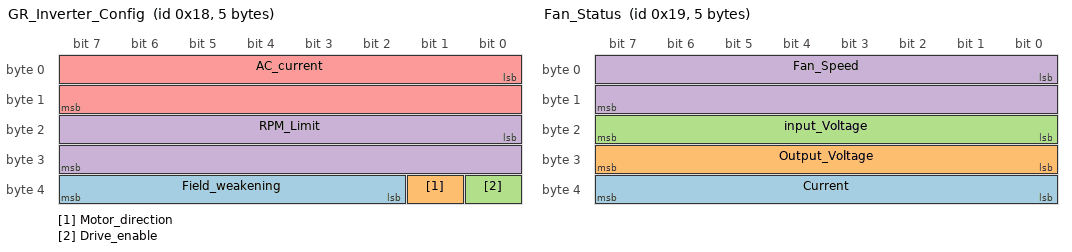
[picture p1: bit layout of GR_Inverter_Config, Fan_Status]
BO_ 24 GR_Inverter_Config: 5 GR_Inverter_1

 SG_ Field_weakening : 34|6@1+ (1,0) [0.0|1.0] "Enable" Vector__XXX

 SG_ Motor_direction : 33|1@1+ (1,0) [0.0|1.0] "Enable" Vector__XXX

 SG_ Drive_enable : 32|1@1+ (1,0) [0.0|1.0] "Enable" Vector__XXX

 SG_ RPM_Limit : 16|16@1+ (1,0) [0.0|65535.0] "RPM" Vector__XXX

 SG_ AC_current : 0|16@1+ (1,0) [0.0|65535.0] "Amps" Vector__XXX

BO_ 25 Fan_Status: 5 Fan_Controller_1

 SG_ Current : 32|8@1+ (1,0) [0.0|255.0] "Amps" Vector__XXX

 SG_ Output_Voltage : 24|8@1+ (1,0) [0.0|255.0] "Volts" Vector__XXX

 SG_ input_Voltage : 16|8@1+ (1,0) [0.0|255.0] "Volts" Vector__XXX

 SG_ Fan_Speed : 0|16@1+ (1,0) [0.0|65535.0] "RPM" Vector__XXX

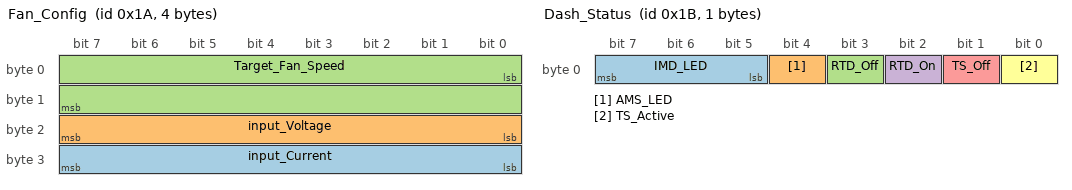
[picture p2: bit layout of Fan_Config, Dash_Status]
BO_ 26 Fan_Config: 4 Fan_Controller_1

 SG_ input_Current : 24|8@1+ (1,0) [0.0|255.0] "Amps" Vector__XXX

 SG_ input_Voltage : 16|8@1+ (1,0) [0.0|255.0] "Volts" Vector__XXX

 SG_ Target_Fan_Speed : 0|16@1+ (1,0) [0.0|65535.0] "RPM" Vector__XXX

BO_ 27 Dash_Status: 1 Dash_Panel

 SG_ IMD_LED : 5|3@1+ (1,0) [0.0|1.0] "Bool" Vector__XXX

 SG_ AMS_LED : 4|1@1+ (1,0) [0.0|1.0] "Bool" Vector__XXX

 SG_ RTD_Off : 3|1@1+ (1,0) [0.0|1.0] "Bool" Vector__XXX

 SG_ RTD_On : 2|1@1+ (1,0) [0.0|1.0] "Bool" Vector__XXX

 SG_ TS_Off : 1|1@1+ (1,0) [0.0|1.0] "Bool" Vector__XXX

 SG_ TS_Active : 0|1@1+ (1,0) [0.0|1.0] "Bool" Vector__XXX

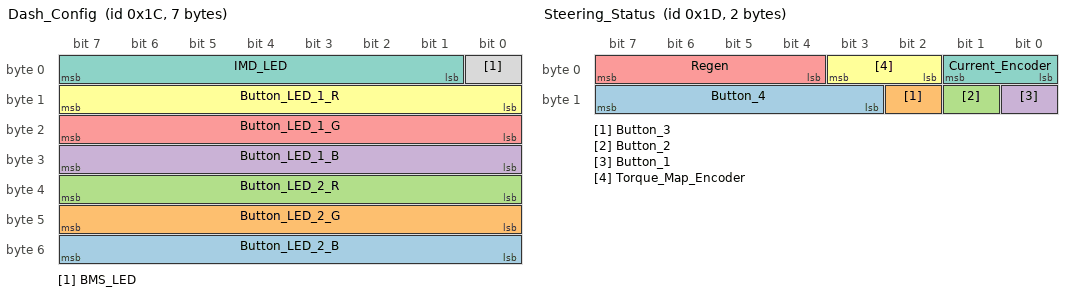
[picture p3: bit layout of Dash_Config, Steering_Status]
BO_ 28 Dash_Config: 7 Dash_Panel

 SG_ Button_LED_2_B : 48|8@1+ (1,0) [0.0|255.0] "RGB" Vector__XXX

 SG_ Button_LED_2_G : 40|8@1+ (1,0) [0.0|255.0] "RGB" Vector__XXX

 SG_ Button_LED_2_R : 32|8@1+ (1,0) [0.0|255.0] "RGB" Vector__XXX

 SG_ Button_LED_1_B : 24|8@1+ (1,0) [0.0|255.0] "RGB" Vector__XXX

 SG_ Button_LED_1_G : 16|8@1+ (1,0) [0.0|255.0] "RGB" Vector__XXX

 SG_ Button_LED_1_R : 8|8@1+ (1,0) [0.0|255.0] "RGB" Vector__XXX

 SG_ IMD_LED : 1|7@1+ (1,0) [0.0|1.0] "Bool" Vector__XXX

 SG_ BMS_LED : 0|1@1+ (1,0) [0.0|1.0] "Bool" Vector__XXX

BO_ 29 Steering_Status: 2 Steering_Wheel

 SG_ Button_4 : 11|5@1+ (1,0) [0.0|1.0] "Bool" Vector__XXX

 SG_ Button_3 : 10|1@1+ (1,0) [0.0|1.0] "Bool" Vector__XXX

 SG_ Button_2 : 9|1@1+ (1,0) [0.0|1.0] "Bool" Vector__XXX

 SG_ Button_1 : 8|1@1+ (1,0) [0.0|1.0] "Bool" Vector__XXX

 SG_ Regen : 4|4@1+ (1,0) [0|0] "" Vector__XXX

 SG_ Torque_Map_Encoder : 2|2@1+ (1,0) [0|0] "" Vector__XXX

 SG_ Current_Encoder : 0|2@1+ (1,0) [0|0] "" Vector__XXX

BO_ 30 Steering_Config: 0 Steering_Wheel

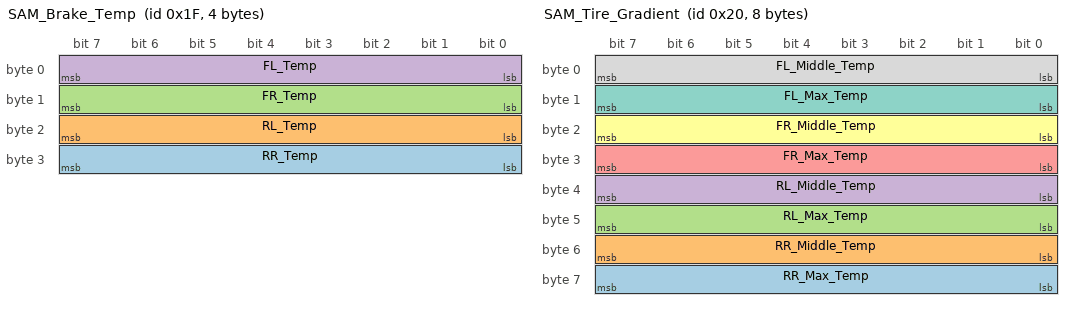
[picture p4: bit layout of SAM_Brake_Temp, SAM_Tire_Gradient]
BO_ 31 SAM_Brake_Temp: 4 SAM1

 SG_ RR_Temp : 24|8@1+ (1,0) [0.0|255.0] "Celsius" Vector__XXX

 SG_ RL_Temp : 16|8@1+ (1,0) [0.0|255.0] "Celsius" Vector__XXX

 SG_ FR_Temp : 8|8@1+ (1,0) [0.0|255.0] "Celsius" Vector__XXX

 SG_ FL_Temp : 0|8@1+ (1,0) [0.0|255.0] "Celsius" Vector__XXX

BO_ 32 SAM_Tire_Gradient: 8 SAM1

 SG_ RR_Max_Temp : 56|8@1+ (1,0) [0.0|255.0] "Celsius" Vector__XXX

 SG_ RR_Middle_Temp : 48|8@1+ (1,0) [0.0|255.0] "Celsius" Vector__XXX

 SG_ RL_Max_Temp : 40|8@1+ (1,0) [0.0|255.0] "Celsius" Vector__XXX

 SG_ RL_Middle_Temp : 32|8@1+ (1,0) [0.0|255.0] "Celsius" Vector__XXX

 SG_ FR_Max_Temp : 24|8@1+ (1,0) [0.0|255.0] "Celsius" Vector__XXX

 SG_ FR_Middle_Temp : 16|8@1+ (1,0) [0.0|255.0] "Celsius" Vector__XXX

 SG_ FL_Max_Temp : 8|8@1+ (1,0) [0.0|255.0] "Celsius" Vector__XXX

 SG_ FL_Middle_Temp : 0|8@1+ (1,0) [0.0|255.0] "Celsius" Vector__XXX

BO_ 33 SAM_IMU: 20 SAM1

 SG_ RR_Yaw_Rate : 144|16@1+ (1,0) [0.0|65535.0] "(°/s)" Vector__XXX

 SG_ RL_Yaw_Rate : 128|16@1+ (1,0) [0.0|65535.0] "(°/s)" Vector__XXX

 SG_ FR_Yaw_Rate : 112|16@1+ (1,0) [0.0|65535.0] "(°/s)" Vector__XXX

 SG_ FL_Yaw_Rate : 96|16@1+ (1,0) [0.0|65535.0] "(°/s)" Vector__XXX

 SG_ Central_Yaw_Rate : 80|16@1+ (1,0) [0.0|65535.0] "(°/s)" Vector__XXX

 SG_ RR_Accel_Z : 72|8@1+ (1,0) [0.0|255.0] "Meters/s^2" Vector__XXX

 SG_ RL_Accel_Z : 64|8@1+ (1,0) [0.0|255.0] "Meters/s^2" Vector__XXX

 SG_ FR_Accel_Z : 56|8@1+ (1,0) [0.0|255.0] "Meters/s^2" Vector__XXX

 SG_ FL_Accel_Z : 48|8@1+ (1,0) [0.0|255.0] "Meters/s^2" Vector__XXX

 SG_ Central_Accel_Z : 32|16@1+ (1,0) [0.0|65535.0] "Meters/s^2" Vector__XXX

 SG_ Central_Accel_Y : 16|16@1+ (1,0) [0.0|65535.0] "Meters/s^2" Vector__XXX

 SG_ Central_Accel_X : 0|16@1+ (1,0) [0.0|65535.0] "Meters/s^2" Vector__XXX

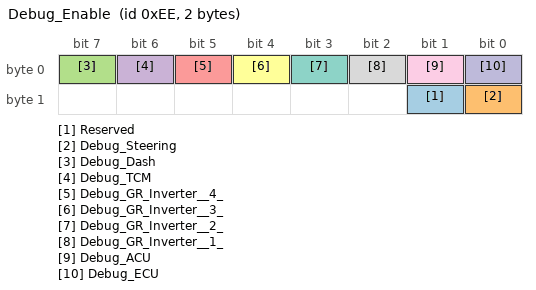
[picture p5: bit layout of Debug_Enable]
BO_ 238 Debug_Enable: 2 Debugger

 SG_ Reserved : 9|1@1+ (1,0) [0|0] "" Vector__XXX

 SG_ Debug_Steering : 8|1@1+ (1,0) [0|0] "" Vector__XXX

 SG_ Debug_Dash : 7|1@1+ (1,0) [0|0] "" Vector__XXX

 SG_ Debug_TCM : 6|1@1+ (1,0) [0|0] "" Vector__XXX

 SG_ Debug_GR_Inverter__4_ : 5|1@1+ (1,0) [0|0] "" Vector__XXX

 SG_ Debug_GR_Inverter__3_ : 4|1@1+ (1,0) [0|0] "" Vector__XXX

 SG_ Debug_GR_Inverter__2_ : 3|1@1+ (1,0) [0|0] "" Vector__XXX

 SG_ Debug_GR_Inverter__1_ : 2|1@1+ (1,0) [0|0] "" Vector__XXX

 SG_ Debug_ACU : 1|1@1+ (1,0) [0|0] "" Vector__XXX

 SG_ Debug_ECU : 0|1@1+ (1,0) [0.0|1.0] "Bool" Vector__XXX
